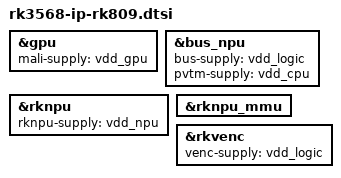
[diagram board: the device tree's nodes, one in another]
&gpu {
	mali-supply = <&vdd_gpu>;
	status = "okay";
};

&bus_npu {
	bus-supply = <&vdd_logic>;
	pvtm-supply = <&vdd_cpu>;
	status = "okay";
};

&rknpu {
	rknpu-supply = <&vdd_npu>;
	status = "okay";
};

&rknpu_mmu {
	status = "okay";
};

&rkvenc {
	venc-supply = <&vdd_logic>;
	status = "okay";
};
